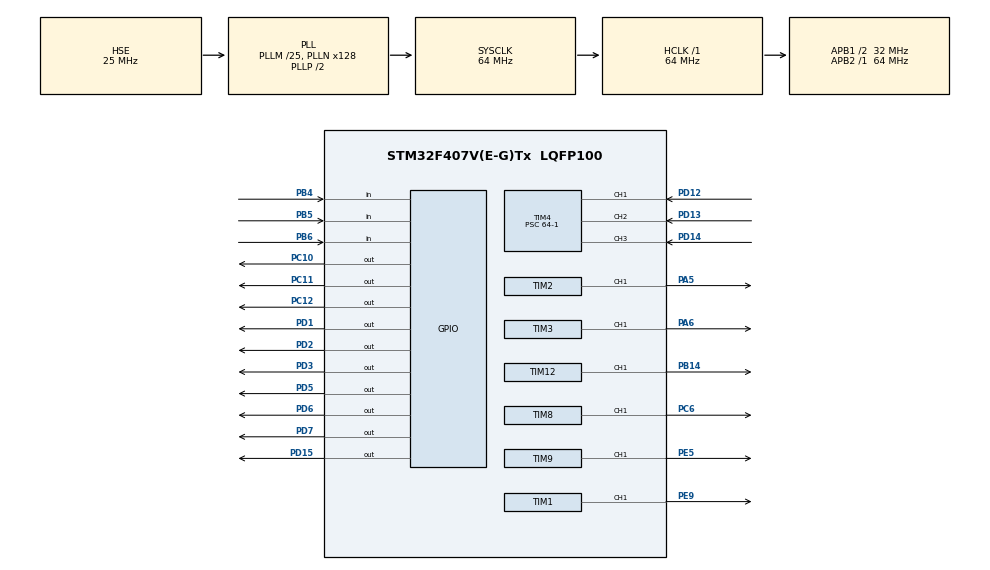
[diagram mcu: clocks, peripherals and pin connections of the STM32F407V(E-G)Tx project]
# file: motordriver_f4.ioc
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Mcu.Family=STM32F4
Mcu.Name=STM32F407V(E-G)Tx
Mcu.Package=LQFP100
NVIC.PriorityGroup=NVIC_PRIORITYGROUP_4
NVIC.TIM4_IRQn=true\:0\:0\:false\:false\:true\:true\:true\:true
PA5.Signal=S_TIM2_CH1_ETR
PA6.Signal=S_TIM3_CH1
PB14.Signal=S_TIM12_CH1
PB4.Signal=GPIO_Input
PB5.Signal=GPIO_Input
PB6.Signal=GPIO_Input
PC10.Signal=GPIO_Output
PC11.Signal=GPIO_Output
PC12.Signal=GPIO_Output
PC6.Signal=S_TIM8_CH1
PD1.Signal=GPIO_Output
PD12.Signal=S_TIM4_CH1
PD13.Signal=S_TIM4_CH2
PD14.Signal=S_TIM4_CH3
PD15.Signal=GPIO_Output
PD2.Signal=GPIO_Output
PD3.Signal=GPIO_Output
PD5.Signal=GPIO_Output
PD6.Signal=GPIO_Output
PD7.Signal=GPIO_Output
PE5.Signal=S_TIM9_CH1
PE9.Signal=S_TIM1_CH1
PH0-OSC_IN.Mode=HSE-External-Oscillator
PH0-OSC_IN.Signal=RCC_OSC_IN
PH1-OSC_OUT.Mode=HSE-External-Oscillator
PH1-OSC_OUT.Signal=RCC_OSC_OUT
ProjectManager.HeapSize=0x200
ProjectManager.StackSize=0x400
ProjectManager.TargetToolchain=STM32CubeIDE
RCC.48MHZClocksFreq_Value=32000000
RCC.AHBFreq_Value=64000000
RCC.APB1CLKDivider=RCC_HCLK_DIV2
RCC.APB1Freq_Value=32000000
RCC.APB1TimFreq_Value=64000000
RCC.APB2Freq_Value=64000000
RCC.APB2TimFreq_Value=64000000
RCC.CortexFreq_Value=64000000
RCC.HCLKFreq_Value=64000000
RCC.HSE_VALUE=25000000
RCC.HSI_VALUE=16000000
RCC.LSE_VALUE=32768
RCC.PLLM=25
RCC.PLLN=128
RCC.PLLSourceVirtual=RCC_PLLSOURCE_HSE
RCC.SYSCLKFreq_VALUE=64000000
RCC.SYSCLKSource=RCC_SYSCLKSOURCE_PLLCLK
RCC.VCOOutputFreq_Value=128000000
SH.S_TIM12_CH1.0=TIM12_CH1,PWM Generation1 CH1
SH.S_TIM1_CH1.0=TIM1_CH1,PWM Generation1 CH1
SH.S_TIM2_CH1_ETR.0=TIM2_CH1,PWM Generation1 CH1
SH.S_TIM3_CH1.0=TIM3_CH1,PWM Generation1 CH1
SH.S_TIM4_CH1.0=TIM4_CH1,Input_Capture1_from_TI1
SH.S_TIM4_CH2.0=TIM4_CH2,Input_Capture2_from_TI2
SH.S_TIM4_CH3.0=TIM4_CH3,Input_Capture3_from_TI3
SH.S_TIM8_CH1.0=TIM8_CH1,PWM Generation1 CH1
SH.S_TIM9_CH1.0=TIM9_CH1,PWM Generation1 CH1
TIM1.Channel-PWM\ Generation1\ CH1=TIM_CHANNEL_1
TIM1.Period=100-1
TIM1.Prescaler=64-1
TIM12.Channel-PWM\ Generation1\ CH1=TIM_CHANNEL_1
TIM12.Period=100-1
TIM12.Prescaler=64-1
TIM2.Channel-PWM\ Generation1\ CH1=TIM_CHANNEL_1
TIM2.Period=100-1
TIM2.Prescaler=64-1
TIM3.Channel-PWM\ Generation1\ CH1=TIM_CHANNEL_1
TIM3.Period=100-1
TIM3.Prescaler=64-1
TIM4.Channel-Input_Capture1_from_TI1=TIM_CHANNEL_1
TIM4.Channel-Input_Capture2_from_TI2=TIM_CHANNEL_2
TIM4.Channel-Input_Capture3_from_TI3=TIM_CHANNEL_3
TIM4.Prescaler=64-1
TIM8.Channel-PWM\ Generation1\ CH1=TIM_CHANNEL_1
TIM8.Period=100-1
TIM8.Prescaler=64-1
TIM9.Channel-PWM\ Generation1\ CH1=TIM_CHANNEL_1
TIM9.Period=100-1
TIM9.Prescaler=64-1
VP_TIM12_VS_ClockSourceINT.Mode=Internal
VP_TIM1_VS_ClockSourceINT.Mode=Internal
VP_TIM2_VS_ClockSourceINT.Mode=Internal
VP_TIM3_VS_ClockSourceINT.Mode=Internal
VP_TIM4_VS_ClockSourceINT.Mode=Internal
VP_TIM8_VS_ClockSourceINT.Mode=Internal
VP_TIM9_VS_ClockSourceINT.Mode=Internal
board=custom

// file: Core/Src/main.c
/* USER CODE BEGIN Header */
/**
  ******************************************************************************
  * @file           : main.c
  * @brief          : Main program body
  ******************************************************************************
  * @attention
  *
  * Copyright (c) 2024 STMicroelectronics.
  * All rights reserved.
  *
  * This software is licensed under terms that can be found in the LICENSE file
  * in the root directory of this software component.
  * If no LICENSE file comes with this software, it is provided AS-IS.
  *
  ******************************************************************************
  */
/* USER CODE END Header */
#include "main.h"

/* USER CODE BEGIN Includes */
#include "motordriver.h"
/* USER CODE END Includes */

TIM_HandleTypeDef htim1;
TIM_HandleTypeDef htim2;
TIM_HandleTypeDef htim3;
TIM_HandleTypeDef htim4;
TIM_HandleTypeDef htim8;
TIM_HandleTypeDef htim9;
TIM_HandleTypeDef htim12;

/* USER CODE BEGIN PV */
//following variables for testing purposes only
double *d_dutyx,*d_dutyy,*d_dutyz,*f_dutyx,*f_dutyy,*f_dutyz;
/* USER CODE END PV */

void SystemClock_Config(void);
static void MX_GPIO_Init(void);
static void MX_TIM1_Init(void);
static void MX_TIM2_Init(void);
static void MX_TIM3_Init(void);
static void MX_TIM4_Init(void);
static void MX_TIM8_Init(void);
static void MX_TIM9_Init(void);
static void MX_TIM12_Init(void);

int main(void)
{

  /* MCU Configuration--------------------------------------------------------*/

  /* Reset of all peripherals, Initializes the Flash interface and the Systick. */
  HAL_Init();

  /* Configure the system clock */
  SystemClock_Config();

  /* Initialize all configured peripherals */
  MX_GPIO_Init();
  MX_TIM1_Init();
  MX_TIM2_Init();
  MX_TIM3_Init();
  MX_TIM4_Init();
  MX_TIM8_Init();
  MX_TIM9_Init();
  MX_TIM12_Init();
  /* USER CODE BEGIN 2 */

  set_desired_motorx(50,1);
  set_desired_motory(70,1);
  set_desired_motorz(30,1);

  HAL_Delay(5000);

  set_desired_motorx(80,1);
    set_desired_motory(40,1);
    set_desired_motorz(32,1);

//    maintain_rpm_x();
//    maintain_rpm_y();
//    maintain_rpm_z();
  /* USER CODE END 2 */

  /* Infinite loop */
  while (1)
  {

  }
}

void SystemClock_Config(void)
{
  RCC_OscInitTypeDef RCC_OscInitStruct = {0};
  RCC_ClkInitTypeDef RCC_ClkInitStruct = {0};

  /** Configure the main internal regulator output voltage
  */
  __HAL_RCC_PWR_CLK_ENABLE();
  __HAL_PWR_VOLTAGESCALING_CONFIG(PWR_REGULATOR_VOLTAGE_SCALE1);

  /** Initializes the RCC Oscillators according to the specified parameters
  * in the RCC_OscInitTypeDef structure.
  */
  RCC_OscInitStruct.OscillatorType = RCC_OSCILLATORTYPE_HSE;
  RCC_OscInitStruct.HSEState = RCC_HSE_ON;
  RCC_OscInitStruct.PLL.PLLState = RCC_PLL_ON;
  RCC_OscInitStruct.PLL.PLLSource = RCC_PLLSOURCE_HSE;
  RCC_OscInitStruct.PLL.PLLM = 25;
  RCC_OscInitStruct.PLL.PLLN = 128;
  RCC_OscInitStruct.PLL.PLLP = RCC_PLLP_DIV2;
  RCC_OscInitStruct.PLL.PLLQ = 4;
  if (HAL_RCC_OscConfig(&RCC_OscInitStruct) != HAL_OK)
  {
    Error_Handler();
  }

  /** Initializes the CPU, AHB and APB buses clocks
  */
  RCC_ClkInitStruct.ClockType = RCC_CLOCKTYPE_HCLK|RCC_CLOCKTYPE_SYSCLK
                              |RCC_CLOCKTYPE_PCLK1|RCC_CLOCKTYPE_PCLK2;
  RCC_ClkInitStruct.SYSCLKSource = RCC_SYSCLKSOURCE_PLLCLK;
  RCC_ClkInitStruct.AHBCLKDivider = RCC_SYSCLK_DIV1;
  RCC_ClkInitStruct.APB1CLKDivider = RCC_HCLK_DIV2;
  RCC_ClkInitStruct.APB2CLKDivider = RCC_HCLK_DIV1;

  if (HAL_RCC_ClockConfig(&RCC_ClkInitStruct, FLASH_LATENCY_2) != HAL_OK)
  {
    Error_Handler();
  }
}

static void MX_TIM1_Init(void)
{

  TIM_ClockConfigTypeDef sClockSourceConfig = {0};
  TIM_MasterConfigTypeDef sMasterConfig = {0};
  TIM_OC_InitTypeDef sConfigOC = {0};
  TIM_BreakDeadTimeConfigTypeDef sBreakDeadTimeConfig = {0};

  htim1.Instance = TIM1;
  htim1.Init.Prescaler = 64-1;
  htim1.Init.CounterMode = TIM_COUNTERMODE_UP;
  htim1.Init.Period = 100-1;
  htim1.Init.ClockDivision = TIM_CLOCKDIVISION_DIV1;
  htim1.Init.RepetitionCounter = 0;
  htim1.Init.AutoReloadPreload = TIM_AUTORELOAD_PRELOAD_DISABLE;
  if (HAL_TIM_Base_Init(&htim1) != HAL_OK)
  {
    Error_Handler();
  }
  sClockSourceConfig.ClockSource = TIM_CLOCKSOURCE_INTERNAL;
  if (HAL_TIM_ConfigClockSource(&htim1, &sClockSourceConfig) != HAL_OK)
  {
    Error_Handler();
  }
  if (HAL_TIM_PWM_Init(&htim1) != HAL_OK)
  {
    Error_Handler();
  }
  sMasterConfig.MasterOutputTrigger = TIM_TRGO_RESET;
  sMasterConfig.MasterSlaveMode = TIM_MASTERSLAVEMODE_DISABLE;
  if (HAL_TIMEx_MasterConfigSynchronization(&htim1, &sMasterConfig) != HAL_OK)
  {
    Error_Handler();
  }
  sConfigOC.OCMode = TIM_OCMODE_PWM1;
  sConfigOC.Pulse = 0;
  sConfigOC.OCPolarity = TIM_OCPOLARITY_HIGH;
  sConfigOC.OCNPolarity = TIM_OCNPOLARITY_HIGH;
  sConfigOC.OCFastMode = TIM_OCFAST_DISABLE;
  sConfigOC.OCIdleState = TIM_OCIDLESTATE_RESET;
  sConfigOC.OCNIdleState = TIM_OCNIDLESTATE_RESET;
  if (HAL_TIM_PWM_ConfigChannel(&htim1, &sConfigOC, TIM_CHANNEL_1) != HAL_OK)
  {
    Error_Handler();
  }
  sBreakDeadTimeConfig.OffStateRunMode = TIM_OSSR_DISABLE;
  sBreakDeadTimeConfig.OffStateIDLEMode = TIM_OSSI_DISABLE;
  sBreakDeadTimeConfig.LockLevel = TIM_LOCKLEVEL_OFF;
  sBreakDeadTimeConfig.DeadTime = 0;
  sBreakDeadTimeConfig.BreakState = TIM_BREAK_DISABLE;
  sBreakDeadTimeConfig.BreakPolarity = TIM_BREAKPOLARITY_HIGH;
  sBreakDeadTimeConfig.AutomaticOutput = TIM_AUTOMATICOUTPUT_DISABLE;
  if (HAL_TIMEx_ConfigBreakDeadTime(&htim1, &sBreakDeadTimeConfig) != HAL_OK)
  {
    Error_Handler();
  }
  HAL_TIM_MspPostInit(&htim1);

}

static void MX_TIM2_Init(void)
{

  TIM_ClockConfigTypeDef sClockSourceConfig = {0};
  TIM_MasterConfigTypeDef sMasterConfig = {0};
  TIM_OC_InitTypeDef sConfigOC = {0};

  htim2.Instance = TIM2;
  htim2.Init.Prescaler = 64-1;
  htim2.Init.CounterMode = TIM_COUNTERMODE_UP;
  htim2.Init.Period = 100-1;
  htim2.Init.ClockDivision = TIM_CLOCKDIVISION_DIV1;
  htim2.Init.AutoReloadPreload = TIM_AUTORELOAD_PRELOAD_DISABLE;
  if (HAL_TIM_Base_Init(&htim2) != HAL_OK)
  {
    Error_Handler();
  }
  sClockSourceConfig.ClockSource = TIM_CLOCKSOURCE_INTERNAL;
  if (HAL_TIM_ConfigClockSource(&htim2, &sClockSourceConfig) != HAL_OK)
  {
    Error_Handler();
  }
  if (HAL_TIM_PWM_Init(&htim2) != HAL_OK)
  {
    Error_Handler();
  }
  sMasterConfig.MasterOutputTrigger = TIM_TRGO_RESET;
  sMasterConfig.MasterSlaveMode = TIM_MASTERSLAVEMODE_DISABLE;
  if (HAL_TIMEx_MasterConfigSynchronization(&htim2, &sMasterConfig) != HAL_OK)
  {
    Error_Handler();
  }
  sConfigOC.OCMode = TIM_OCMODE_PWM1;
  sConfigOC.Pulse = 0;
  sConfigOC.OCPolarity = TIM_OCPOLARITY_HIGH;
  sConfigOC.OCFastMode = TIM_OCFAST_DISABLE;
  if (HAL_TIM_PWM_ConfigChannel(&htim2, &sConfigOC, TIM_CHANNEL_1) != HAL_OK)
  {
    Error_Handler();
  }
  HAL_TIM_MspPostInit(&htim2);

}

static void MX_TIM3_Init(void)
{

  TIM_ClockConfigTypeDef sClockSourceConfig = {0};
  TIM_MasterConfigTypeDef sMasterConfig = {0};
  TIM_OC_InitTypeDef sConfigOC = {0};

  htim3.Instance = TIM3;
  htim3.Init.Prescaler = 64-1;
  htim3.Init.CounterMode = TIM_COUNTERMODE_UP;
  htim3.Init.Period = 100-1;
  htim3.Init.ClockDivision = TIM_CLOCKDIVISION_DIV1;
  htim3.Init.AutoReloadPreload = TIM_AUTORELOAD_PRELOAD_DISABLE;
  if (HAL_TIM_Base_Init(&htim3) != HAL_OK)
  {
    Error_Handler();
  }
  sClockSourceConfig.ClockSource = TIM_CLOCKSOURCE_INTERNAL;
  if (HAL_TIM_ConfigClockSource(&htim3, &sClockSourceConfig) != HAL_OK)
  {
    Error_Handler();
  }
  if (HAL_TIM_PWM_Init(&htim3) != HAL_OK)
  {
    Error_Handler();
  }
  sMasterConfig.MasterOutputTrigger = TIM_TRGO_RESET;
  sMasterConfig.MasterSlaveMode = TIM_MASTERSLAVEMODE_DISABLE;
  if (HAL_TIMEx_MasterConfigSynchronization(&htim3, &sMasterConfig) != HAL_OK)
  {
    Error_Handler();
  }
  sConfigOC.OCMode = TIM_OCMODE_PWM1;
  sConfigOC.Pulse = 0;
  sConfigOC.OCPolarity = TIM_OCPOLARITY_HIGH;
  sConfigOC.OCFastMode = TIM_OCFAST_DISABLE;
  if (HAL_TIM_PWM_ConfigChannel(&htim3, &sConfigOC, TIM_CHANNEL_1) != HAL_OK)
  {
    Error_Handler();
  }
  HAL_TIM_MspPostInit(&htim3);

}

static void MX_TIM4_Init(void)
{

  TIM_ClockConfigTypeDef sClockSourceConfig = {0};
  TIM_MasterConfigTypeDef sMasterConfig = {0};
  TIM_IC_InitTypeDef sConfigIC = {0};

  htim4.Instance = TIM4;
  htim4.Init.Prescaler = 64-1;
  htim4.Init.CounterMode = TIM_COUNTERMODE_UP;
  htim4.Init.Period = 65535;
  htim4.Init.ClockDivision = TIM_CLOCKDIVISION_DIV1;
  htim4.Init.AutoReloadPreload = TIM_AUTORELOAD_PRELOAD_DISABLE;
  if (HAL_TIM_Base_Init(&htim4) != HAL_OK)
  {
    Error_Handler();
  }
  sClockSourceConfig.ClockSource = TIM_CLOCKSOURCE_INTERNAL;
  if (HAL_TIM_ConfigClockSource(&htim4, &sClockSourceConfig) != HAL_OK)
  {
    Error_Handler();
  }
  if (HAL_TIM_IC_Init(&htim4) != HAL_OK)
  {
    Error_Handler();
  }
  sMasterConfig.MasterOutputTrigger = TIM_TRGO_RESET;
  sMasterConfig.MasterSlaveMode = TIM_MASTERSLAVEMODE_DISABLE;
  if (HAL_TIMEx_MasterConfigSynchronization(&htim4, &sMasterConfig) != HAL_OK)
  {
    Error_Handler();
  }
  sConfigIC.ICPolarity = TIM_INPUTCHANNELPOLARITY_RISING;
  sConfigIC.ICSelection = TIM_ICSELECTION_DIRECTTI;
  sConfigIC.ICPrescaler = TIM_ICPSC_DIV1;
  sConfigIC.ICFilter = 0;
  if (HAL_TIM_IC_ConfigChannel(&htim4, &sConfigIC, TIM_CHANNEL_1) != HAL_OK)
  {
    Error_Handler();
  }
  if (HAL_TIM_IC_ConfigChannel(&htim4, &sConfigIC, TIM_CHANNEL_2) != HAL_OK)
  {
    Error_Handler();
  }
  if (HAL_TIM_IC_ConfigChannel(&htim4, &sConfigIC, TIM_CHANNEL_3) != HAL_OK)
  {
    Error_Handler();
  }

}

static void MX_TIM8_Init(void)
{

  TIM_ClockConfigTypeDef sClockSourceConfig = {0};
  TIM_MasterConfigTypeDef sMasterConfig = {0};
  TIM_OC_InitTypeDef sConfigOC = {0};
  TIM_BreakDeadTimeConfigTypeDef sBreakDeadTimeConfig = {0};

  htim8.Instance = TIM8;
  htim8.Init.Prescaler = 64-1;
  htim8.Init.CounterMode = TIM_COUNTERMODE_UP;
  htim8.Init.Period = 100-1;
  htim8.Init.ClockDivision = TIM_CLOCKDIVISION_DIV1;
  htim8.Init.RepetitionCounter = 0;
  htim8.Init.AutoReloadPreload = TIM_AUTORELOAD_PRELOAD_DISABLE;
  if (HAL_TIM_Base_Init(&htim8) != HAL_OK)
  {
    Error_Handler();
  }
  sClockSourceConfig.ClockSource = TIM_CLOCKSOURCE_INTERNAL;
  if (HAL_TIM_ConfigClockSource(&htim8, &sClockSourceConfig) != HAL_OK)
  {
    Error_Handler();
  }
  if (HAL_TIM_PWM_Init(&htim8) != HAL_OK)
  {
    Error_Handler();
  }
  sMasterConfig.MasterOutputTrigger = TIM_TRGO_RESET;
  sMasterConfig.MasterSlaveMode = TIM_MASTERSLAVEMODE_DISABLE;
  if (HAL_TIMEx_MasterConfigSynchronization(&htim8, &sMasterConfig) != HAL_OK)
  {
    Error_Handler();
  }
  sConfigOC.OCMode = TIM_OCMODE_PWM1;
  sConfigOC.Pulse = 0;
  sConfigOC.OCPolarity = TIM_OCPOLARITY_HIGH;
  sConfigOC.OCNPolarity = TIM_OCNPOLARITY_HIGH;
  sConfigOC.OCFastMode = TIM_OCFAST_DISABLE;
  sConfigOC.OCIdleState = TIM_OCIDLESTATE_RESET;
  sConfigOC.OCNIdleState = TIM_OCNIDLESTATE_RESET;
  if (HAL_TIM_PWM_ConfigChannel(&htim8, &sConfigOC, TIM_CHANNEL_1) != HAL_OK)
  {
    Error_Handler();
  }
  sBreakDeadTimeConfig.OffStateRunMode = TIM_OSSR_DISABLE;
  sBreakDeadTimeConfig.OffStateIDLEMode = TIM_OSSI_DISABLE;
  sBreakDeadTimeConfig.LockLevel = TIM_LOCKLEVEL_OFF;
  sBreakDeadTimeConfig.DeadTime = 0;
  sBreakDeadTimeConfig.BreakState = TIM_BREAK_DISABLE;
  sBreakDeadTimeConfig.BreakPolarity = TIM_BREAKPOLARITY_HIGH;
  sBreakDeadTimeConfig.AutomaticOutput = TIM_AUTOMATICOUTPUT_DISABLE;
  if (HAL_TIMEx_ConfigBreakDeadTime(&htim8, &sBreakDeadTimeConfig) != HAL_OK)
  {
    Error_Handler();
  }
  HAL_TIM_MspPostInit(&htim8);

}

static void MX_TIM9_Init(void)
{

  TIM_ClockConfigTypeDef sClockSourceConfig = {0};
  TIM_OC_InitTypeDef sConfigOC = {0};

  htim9.Instance = TIM9;
  htim9.Init.Prescaler = 64-1;
  htim9.Init.CounterMode = TIM_COUNTERMODE_UP;
  htim9.Init.Period = 100-1;
  htim9.Init.ClockDivision = TIM_CLOCKDIVISION_DIV1;
  htim9.Init.AutoReloadPreload = TIM_AUTORELOAD_PRELOAD_DISABLE;
  if (HAL_TIM_Base_Init(&htim9) != HAL_OK)
  {
    Error_Handler();
  }
  sClockSourceConfig.ClockSource = TIM_CLOCKSOURCE_INTERNAL;
  if (HAL_TIM_ConfigClockSource(&htim9, &sClockSourceConfig) != HAL_OK)
  {
    Error_Handler();
  }
  if (HAL_TIM_PWM_Init(&htim9) != HAL_OK)
  {
    Error_Handler();
  }
  sConfigOC.OCMode = TIM_OCMODE_PWM1;
  sConfigOC.Pulse = 0;
  sConfigOC.OCPolarity = TIM_OCPOLARITY_HIGH;
  sConfigOC.OCFastMode = TIM_OCFAST_DISABLE;
  if (HAL_TIM_PWM_ConfigChannel(&htim9, &sConfigOC, TIM_CHANNEL_1) != HAL_OK)
  {
    Error_Handler();
  }
  HAL_TIM_MspPostInit(&htim9);

}

static void MX_TIM12_Init(void)
{

  TIM_ClockConfigTypeDef sClockSourceConfig = {0};
  TIM_OC_InitTypeDef sConfigOC = {0};

  htim12.Instance = TIM12;
  htim12.Init.Prescaler = 64-1;
  htim12.Init.CounterMode = TIM_COUNTERMODE_UP;
  htim12.Init.Period = 100-1;
  htim12.Init.ClockDivision = TIM_CLOCKDIVISION_DIV1;
  htim12.Init.AutoReloadPreload = TIM_AUTORELOAD_PRELOAD_DISABLE;
  if (HAL_TIM_Base_Init(&htim12) != HAL_OK)
  {
    Error_Handler();
  }
  sClockSourceConfig.ClockSource = TIM_CLOCKSOURCE_INTERNAL;
  if (HAL_TIM_ConfigClockSource(&htim12, &sClockSourceConfig) != HAL_OK)
  {
    Error_Handler();
  }
  if (HAL_TIM_PWM_Init(&htim12) != HAL_OK)
  {
    Error_Handler();
  }
  sConfigOC.OCMode = TIM_OCMODE_PWM1;
  sConfigOC.Pulse = 0;
  sConfigOC.OCPolarity = TIM_OCPOLARITY_HIGH;
  sConfigOC.OCFastMode = TIM_OCFAST_DISABLE;
  if (HAL_TIM_PWM_ConfigChannel(&htim12, &sConfigOC, TIM_CHANNEL_1) != HAL_OK)
  {
    Error_Handler();
  }
  HAL_TIM_MspPostInit(&htim12);

}

static void MX_GPIO_Init(void)
{
  GPIO_InitTypeDef GPIO_InitStruct = {0};

  /* GPIO Ports Clock Enable */
  __HAL_RCC_GPIOE_CLK_ENABLE();
  __HAL_RCC_GPIOH_CLK_ENABLE();
  __HAL_RCC_GPIOA_CLK_ENABLE();
  __HAL_RCC_GPIOB_CLK_ENABLE();
  __HAL_RCC_GPIOD_CLK_ENABLE();
  __HAL_RCC_GPIOC_CLK_ENABLE();

  /*Configure GPIO pin Output Level */
  HAL_GPIO_WritePin(GPIOD, GPIO_PIN_15|GPIO_PIN_1|GPIO_PIN_2|GPIO_PIN_3
                          |GPIO_PIN_5|GPIO_PIN_6|GPIO_PIN_7, GPIO_PIN_RESET);

  /*Configure GPIO pin Output Level */
  HAL_GPIO_WritePin(GPIOC, GPIO_PIN_10|GPIO_PIN_11|GPIO_PIN_12, GPIO_PIN_RESET);

  /*Configure GPIO pins : PD15 PD1 PD2 PD3
                           PD5 PD6 PD7 */
  GPIO_InitStruct.Pin = GPIO_PIN_15|GPIO_PIN_1|GPIO_PIN_2|GPIO_PIN_3
                          |GPIO_PIN_5|GPIO_PIN_6|GPIO_PIN_7;
  GPIO_InitStruct.Mode = GPIO_MODE_OUTPUT_PP;
  GPIO_InitStruct.Pull = GPIO_NOPULL;
  GPIO_InitStruct.Speed = GPIO_SPEED_FREQ_LOW;
  HAL_GPIO_Init(GPIOD, &GPIO_InitStruct);

  /*Configure GPIO pins : PC10 PC11 PC12 */
  GPIO_InitStruct.Pin = GPIO_PIN_10|GPIO_PIN_11|GPIO_PIN_12;
  GPIO_InitStruct.Mode = GPIO_MODE_OUTPUT_PP;
  GPIO_InitStruct.Pull = GPIO_NOPULL;
  GPIO_InitStruct.Speed = GPIO_SPEED_FREQ_LOW;
  HAL_GPIO_Init(GPIOC, &GPIO_InitStruct);

  /*Configure GPIO pins : PB4 PB5 PB6 */
  GPIO_InitStruct.Pin = GPIO_PIN_4|GPIO_PIN_5|GPIO_PIN_6;
  GPIO_InitStruct.Mode = GPIO_MODE_INPUT;
  GPIO_InitStruct.Pull = GPIO_NOPULL;
  HAL_GPIO_Init(GPIOB, &GPIO_InitStruct);

/* USER CODE BEGIN MX_GPIO_Init_2 */
  motor_initialize(&GPIO_InitStruct);
/* USER CODE END MX_GPIO_Init_2 */
}

void Error_Handler(void)
{
  __disable_irq();
  while (1)
  {
  }
}
